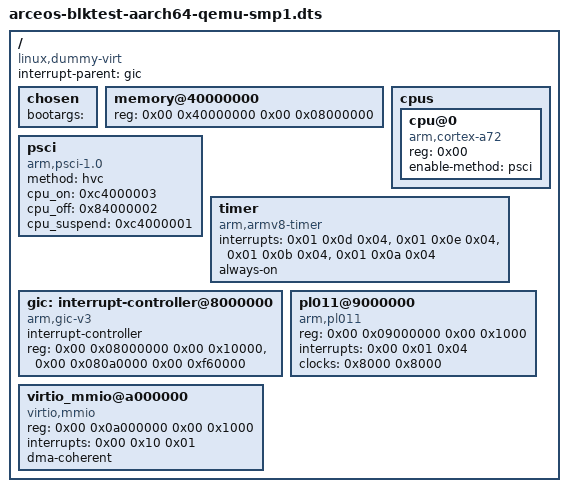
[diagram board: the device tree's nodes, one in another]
/dts-v1/;

/ {
    compatible = "linux,dummy-virt";
    #address-cells = <0x02>;
    #size-cells = <0x02>;
    interrupt-parent = <&gic>;

    chosen {
        bootargs = "";
    };

    memory@40000000 {
        device_type = "memory";
        reg = <0x00 0x40000000 0x00 0x08000000>;
    };

    cpus {
        #address-cells = <0x01>;
        #size-cells = <0x00>;

        cpu@0 {
            device_type = "cpu";
            compatible = "arm,cortex-a72";
            reg = <0x00>;
            enable-method = "psci";
        };
    };

    psci {
        compatible = "arm,psci-1.0", "arm,psci-0.2", "arm,psci";
        method = "hvc";
        cpu_on = <0xc4000003>;
        cpu_off = <0x84000002>;
        cpu_suspend = <0xc4000001>;
    };

    timer {
        compatible = "arm,armv8-timer";
        interrupts = <0x01 0x0d 0x04>,
                     <0x01 0x0e 0x04>,
                     <0x01 0x0b 0x04>,
                     <0x01 0x0a 0x04>;
        always-on;
    };

    gic: interrupt-controller@8000000 {
        compatible = "arm,gic-v3";
        #interrupt-cells = <0x03>;
        interrupt-controller;
        reg = <0x00 0x08000000 0x00 0x10000>,
              <0x00 0x080a0000 0x00 0xf60000>;
        #address-cells = <0x02>;
        #size-cells = <0x02>;
        phandle = <0x8002>;
    };

    pl011@9000000 {
        compatible = "arm,pl011", "arm,primecell";
        reg = <0x00 0x09000000 0x00 0x1000>;
        interrupts = <0x00 0x01 0x04>;
        clock-names = "uartclk", "apb_pclk";
        clocks = <0x8000 0x8000>;
    };

    // Virtio block device at 0x0a000000 (interrupt SPI 16 = 32+16=48)
    virtio_mmio@a000000 {
        compatible = "virtio,mmio";
        reg = <0x00 0x0a000000 0x00 0x1000>;
        interrupts = <0x00 0x10 0x01>;
        dma-coherent;
    };
};
